AUTOSAR XML (schema 314)
package /ComponentType
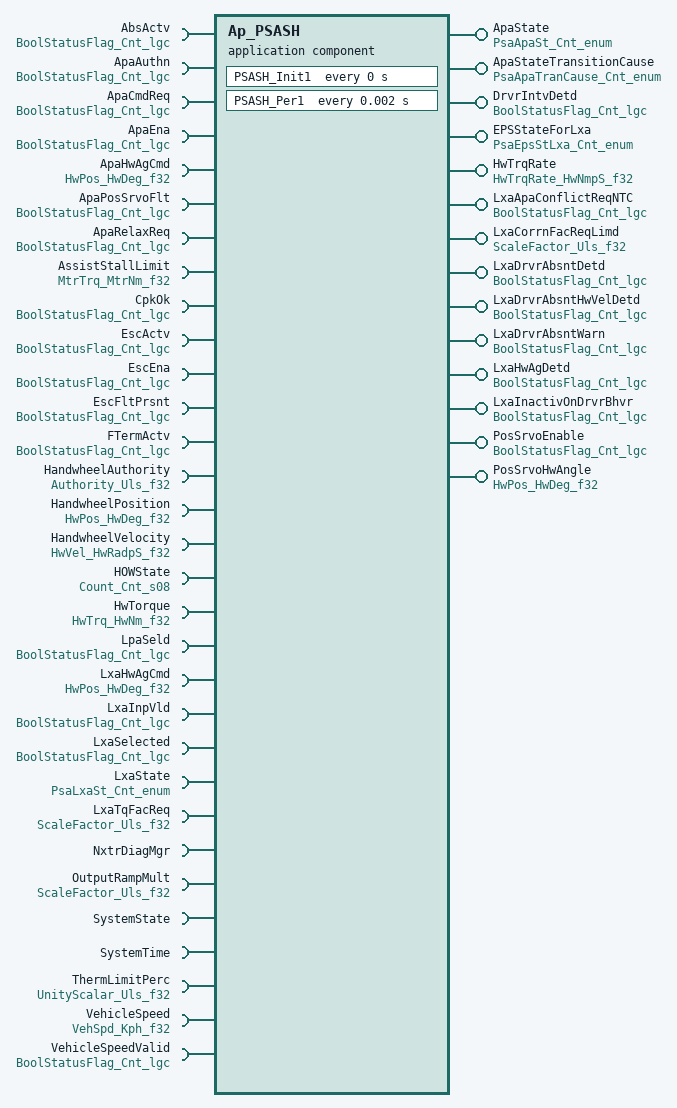
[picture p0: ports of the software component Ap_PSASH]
  application software component type Ap_PSASH
    14 x provide port:
      ApaState: unqueued-sender-com-spec{data-element=Cnt_enum, can-invalidate=false, init-value=D_PSAAPASTINIT_CNT_ENUM}, provided-interface=PsaApaSt_Cnt_enum
      ApaStateTransitionCause: unqueued-sender-com-spec{data-element=Cnt_enum, can-invalidate=false, init-value=D_PSAAPATRANCAUSEINIT_CNT_ENUM}, provided-interface=PsaApaTranCause_Cnt_enum  # Indicates the transition reason of the Automatic Parking Assist State
      DrvrIntvDetd: unqueued-sender-com-spec{data-element=Cnt_lgc, can-invalidate=false, init-value=D_FALSE_CNT_LGC}, provided-interface=BoolStatusFlag_Cnt_lgc  # True -> Hands are on the wheel.
      EPSStateForLxa: unqueued-sender-com-spec{data-element=Cnt_enum, can-invalidate=false, init-value=D_PSAEPSSTLXAINIT_CNT_ENUM}, provided-interface=PsaEpsStLxa_Cnt_enum  # EPS State For LXA
      HwTrqRate: unqueued-sender-com-spec{data-element=HwNmpS_f32, can-invalidate=false, init-value=D_ZERO_ULS_F32}, provided-interface=HwTrqRate_HwNmpS_f32  # Computes Handwheel Torque gradient during LXA command
      LxaApaConflictReqNTC: unqueued-sender-com-spec{data-element=Cnt_lgc, can-invalidate=false, init-value=D_FALSE_CNT_LGC}, provided-interface=BoolStatusFlag_Cnt_lgc  # True means that NTC VLF_20 has been set to FAILED at least one time.
      LxaCorrnFacReqLimd: unqueued-sender-com-spec{data-element=Uls_f32, can-invalidate=false, init-value=D_ZERO_ULS_F32}, provided-interface=ScaleFactor_Uls_f32  # If equal to 1, then the trajectory correction is maximal. If equal to 0, then the trajectory correction is minimal.
      LxaDrvrAbsntDetd: unqueued-sender-com-spec{data-element=Cnt_lgc, can-invalidate=false, init-value=D_FALSE_CNT_LGC}, provided-interface=BoolStatusFlag_Cnt_lgc  # True = Lxa is inactive or driver absent detected
      LxaDrvrAbsntHwVelDetd: unqueued-sender-com-spec{data-element=Cnt_lgc, can-invalidate=false, init-value=D_FALSE_CNT_LGC}, provided-interface=BoolStatusFlag_Cnt_lgc  # True means Lxa has been deactivated on handwheel velocity.
      LxaDrvrAbsntWarn: unqueued-sender-com-spec{data-element=Cnt_lgc, can-invalidate=false, init-value=D_FALSE_CNT_LGC}, provided-interface=BoolStatusFlag_Cnt_lgc  # True means a warning that hands are not on the wheel.
      LxaHwAgDetd: unqueued-sender-com-spec{data-element=Cnt_lgc, can-invalidate=false, init-value=D_FALSE_CNT_LGC}, provided-interface=BoolStatusFlag_Cnt_lgc  # True means LXA has been deactivated on handwheel angle.
      LxaInactivOnDrvrBhvr: unqueued-sender-com-spec{data-element=Cnt_lgc, can-invalidate=false, init-value=D_FALSE_CNT_LGC}, provided-interface=BoolStatusFlag_Cnt_lgc  # LXA Inactive on Driver Behavior
      PosSrvoEnable: unqueued-sender-com-spec{data-element=Cnt_lgc, can-invalidate=false, init-value=D_FALSE_CNT_LGC}, provided-interface=BoolStatusFlag_Cnt_lgc  # True means Position Servo is enabled.
      PosSrvoHwAngle: unqueued-sender-com-spec{data-element=HwDeg_f32, can-invalidate=false, init-value=D_ZERO_ULS_F32}, provided-interface=HwPos_HwDeg_f32  # Tracking angle.
    31 x require port:
      AbsActv: unqueued-receiver-com-spec{data-element=Cnt_lgc, init-value=D_FALSE_CNT_LGC}, required-interface=BoolStatusFlag_Cnt_lgc  # CAN signal indicating whether ABS is active or not.
      ApaAuthn: unqueued-receiver-com-spec{data-element=Cnt_lgc, init-value=D_FALSE_CNT_LGC}, required-interface=BoolStatusFlag_Cnt_lgc  # True: Ignition is running and auto park function is authorized.
      ApaCmdReq: unqueued-receiver-com-spec{data-element=Cnt_lgc, init-value=D_FALSE_CNT_LGC}, required-interface=BoolStatusFlag_Cnt_lgc  # True: Automatic Parking Assist Command is requested.
      ApaEna: unqueued-receiver-com-spec{data-element=Cnt_lgc, init-value=D_FALSE_CNT_LGC}, required-interface=BoolStatusFlag_Cnt_lgc  # True: if the coding variant of Automatic Parking Assist is enabled
      ApaHwAgCmd: unqueued-receiver-com-spec{data-element=HwDeg_f32, init-value=D_ZERO_ULS_F32}, required-interface=HwPos_HwDeg_f32  # Handwheel position set point for Automatic Parking Assist.
      ApaPosSrvoFlt: unqueued-receiver-com-spec{data-element=Cnt_lgc, init-value=D_FALSE_CNT_LGC}, required-interface=BoolStatusFlag_Cnt_lgc  # True: If an NTC is detected due to fact that Automatic Parking ASsist is still active during a vehicle speed greater than a certain threshold
      ApaRelaxReq: unqueued-receiver-com-spec{data-element=Cnt_lgc, init-value=D_FALSE_CNT_LGC}, required-interface=BoolStatusFlag_Cnt_lgc  # True: Temporary request to hold the Automatic Parking Assist command.
      AssistStallLimit: unqueued-receiver-com-spec{data-element=MtrNm_f32, init-value=D_MTRTRQCMDHILMT_MTRNM_F32}, required-interface=MtrTrq_MtrNm_f32  # Motor is stalled when Stall limit is lower or equal than a certain calibrated threshold
      CpkOk: unqueued-receiver-com-spec{data-element=Cnt_lgc, init-value=D_FALSE_CNT_LGC}, required-interface=BoolStatusFlag_Cnt_lgc  # True: All CAN signal used by Automatic Parking Assist are valid.
      EscActv: unqueued-receiver-com-spec{data-element=Cnt_lgc, init-value=D_FALSE_CNT_LGC}, required-interface=BoolStatusFlag_Cnt_lgc  # True: Electrical stability control is active
      EscEna: unqueued-receiver-com-spec{data-element=Cnt_lgc, init-value=D_FALSE_CNT_LGC}, required-interface=BoolStatusFlag_Cnt_lgc  # True: Electronic Stability Control is enabled.
      EscFltPrsnt: unqueued-receiver-com-spec{data-element=Cnt_lgc, init-value=D_TRUE_CNT_LGC}, required-interface=BoolStatusFlag_Cnt_lgc  # True: Fault present on Electronic Stability Control
      FTermActv: unqueued-receiver-com-spec{data-element=Cnt_lgc, init-value=D_FALSE_CNT_LGC}, required-interface=BoolStatusFlag_Cnt_lgc  # True: Fault term is active
      HandwheelAuthority: unqueued-receiver-com-spec{data-element=Uls_f32, init-value=D_ZERO_ULS_F32}, required-interface=Authority_Uls_f32  # Handwheel Authority signal whichis used in order to determine APA State and LXA State.
      HandwheelPosition: unqueued-receiver-com-spec{data-element=HwDeg_f32, init-value=D_ZERO_ULS_F32}, required-interface=HwPos_HwDeg_f32  # Handwheel Position Signal. Used in all kinds of computations: LXA State, APA State and LXA Driver Behavior
      HandwheelVelocity: unqueued-receiver-com-spec{data-element=HwRadpS_f32, init-value=D_ZERO_ULS_F32}, required-interface=HwVel_HwRadpS_f32  # Handwheel Velocity. Used for calculating handwheel velocity thresholds used in LXA Driver Behavior algorithm to determine its outputs.
      HOWState: unqueued-receiver-com-spec{data-element=Cnt_s08, init-value=D_ZERO_CNT_S8}, required-interface=Count_Cnt_s08  # Computes if hands are on the wheel or not with a levelof confident goi'ng from -3 to 3
      HwTorque: unqueued-receiver-com-spec{data-element=HwNm_f32, init-value=D_ZERO_ULS_F32}, required-interface=HwTrq_HwNm_f32  # Standard Handwheel Torque used in LXA Driver Behavior algorithm.
      LpaSeld: unqueued-receiver-com-spec{data-element=Cnt_lgc, init-value=D_FALSE_CNT_LGC}, required-interface=BoolStatusFlag_Cnt_lgc  # To select between LKA (Lane Keeping Assist) & LPA (Lane Positioning Assist). 0 = LPA Not Selected (LKA Active), 1 - Otherwise
      LxaHwAgCmd: unqueued-receiver-com-spec{data-element=HwDeg_f32, init-value=D_ZERO_ULS_F32}, required-interface=HwPos_HwDeg_f32  # Handwheel position set point for LXA
      LxaInpVld: unqueued-receiver-com-spec{data-element=Cnt_lgc, init-value=D_FALSE_CNT_LGC}, required-interface=BoolStatusFlag_Cnt_lgc  # True: CAN signals used by the LXA function are valid
      LxaSelected: unqueued-receiver-com-spec{data-element=Cnt_lgc, init-value=D_FALSE_CNT_LGC}, required-interface=BoolStatusFlag_Cnt_lgc  # Variand coding to enable/disbale the Lxa function
      LxaState: unqueued-receiver-com-spec{data-element=Cnt_enum, init-value=D_PSALXASTINIT_CNT_ENUM}, required-interface=PsaLxaSt_Cnt_enum  # Lane Keeping Assist comand request to change the EPS state for LKA
      LxaTqFacReq: unqueued-receiver-com-spec{data-element=Uls_f32, init-value=D_ZERO_ULS_F32}, required-interface=ScaleFactor_Uls_f32  # A scale factor for LXA Command.
      NxtrDiagMgr: required-com-specs=[GetNTCActive, GetNTCFailed, GetNTCStatus, SetNTCStatus], required-interface=NxtrDiagMgr
      OutputRampMult: unqueued-receiver-com-spec{data-element=Uls_f32, init-value=D_ZERO_ULS_F32}, required-interface=ScaleFactor_Uls_f32  # Signal used in computing internal EPS State which is part of EPS State For Lxa computations.
      SystemState: required-interface=SystemState  # Indicates the system state.
      SystemTime: required-interface=SystemTime
        required-com-specs:
          DtrmnElapsedTime_mS_u16
          DtrmnElapsedTime_mS_u32
          DtrmnElapsedTime_uS_u16
          DtrmnElapsedTime_uS_u32
          GetSystemTime_mS_u32
          GetSystemTime_uS_u32
      ThermLimitPerc: unqueued-receiver-com-spec{data-element=Uls_f32, init-value=D_ZERO_ULS_F32}, required-interface=UnityScalar_Uls_f32  # Thermal Limit is reached when thermal Limit is higher than or equal to a certain calibrated threshold.
      VehicleSpeed: unqueued-receiver-com-spec{data-element=Kph_f32, init-value=D_ZERO_ULS_F32}, required-interface=VehSpd_Kph_f32  # Standard Vehicle Speed signal.
      VehicleSpeedValid: unqueued-receiver-com-spec{data-element=Cnt_lgc, init-value=D_FALSE_CNT_LGC}, required-interface=BoolStatusFlag_Cnt_lgc  # TRUE: Vehicle Speed signal is valid
  internal behavior Ap_PSASH_InternalBehavior: component=Ap_PSASH
    timing event PSASH_Init1_InitEvent: start-on-event=PSASH_Init1, period=0
    timing event TMT_PSASH_Per1: start-on-event=PSASH_Per1, period=0.002
    port-api-options:
      enable-take-address=false, indirect-api=false, port=AbsActv
      enable-take-address=false, indirect-api=false, port=ApaAuthn
      enable-take-address=false, indirect-api=false, port=ApaCmdReq
      enable-take-address=false, indirect-api=false, port=ApaEna
      enable-take-address=false, indirect-api=false, port=ApaHwAgCmd
      enable-take-address=false, indirect-api=false, port=ApaPosSrvoFlt
      enable-take-address=false, indirect-api=false, port=ApaRelaxReq
      enable-take-address=false, indirect-api=false, port=ApaState
      enable-take-address=false, indirect-api=false, port=ApaStateTransitionCause
      enable-take-address=false, indirect-api=false, port=AssistStallLimit
      enable-take-address=false, indirect-api=false, port=CpkOk
      enable-take-address=false, indirect-api=false, port=DrvrIntvDetd
      enable-take-address=false, indirect-api=false, port=EPSStateForLxa
      enable-take-address=false, indirect-api=false, port=EscActv
      enable-take-address=false, indirect-api=false, port=EscEna
      enable-take-address=false, indirect-api=false, port=EscFltPrsnt
      enable-take-address=false, indirect-api=false, port=FTermActv
      enable-take-address=false, indirect-api=false, port=HandwheelAuthority
      enable-take-address=false, indirect-api=false, port=HandwheelPosition
      enable-take-address=false, indirect-api=false, port=HandwheelVelocity
      enable-take-address=false, indirect-api=false, port=HOWState
      enable-take-address=false, indirect-api=false, port=HwTorque
      enable-take-address=false, indirect-api=false, port=HwTrqRate
      enable-take-address=false, indirect-api=false, port=LpaSeld
      enable-take-address=false, indirect-api=false, port=LxaApaConflictReqNTC
      enable-take-address=false, indirect-api=false, port=LxaCorrnFacReqLimd
      enable-take-address=false, indirect-api=false, port=LxaDrvrAbsntDetd
      enable-take-address=false, indirect-api=false, port=LxaDrvrAbsntHwVelDetd
      enable-take-address=false, indirect-api=false, port=LxaDrvrAbsntWarn
      enable-take-address=false, indirect-api=false, port=LxaHwAgCmd
      enable-take-address=false, indirect-api=false, port=LxaHwAgDetd
      enable-take-address=false, indirect-api=false, port=LxaInactivOnDrvrBhvr
      enable-take-address=false, indirect-api=false, port=LxaInpVld
      enable-take-address=false, indirect-api=false, port=LxaSelected
      enable-take-address=false, indirect-api=false, port=LxaState
      enable-take-address=false, indirect-api=false, port=LxaTqFacReq
      enable-take-address=false, indirect-api=false, port=NxtrDiagMgr
      enable-take-address=false, indirect-api=false, port=OutputRampMult
      enable-take-address=false, indirect-api=false, port=PosSrvoEnable
      enable-take-address=false, indirect-api=false, port=PosSrvoHwAngle
      enable-take-address=false, indirect-api=false, port=SystemState
      enable-take-address=false, indirect-api=false, port=SystemTime
      enable-take-address=false, indirect-api=false, port=ThermLimitPerc
      enable-take-address=false, indirect-api=false, port=VehicleSpeed
      enable-take-address=false, indirect-api=false, port=VehicleSpeedValid
    runnable PSASH_Init1  # Function initialization
      sync call SC_NxtrDiagMgr_SetNTCStatus: operation=NxtrDiagMgr.SetNTCStatus, timeout=0
    runnable PSASH_Per1  # Periodic Runnable execute at every 0.002 sec. Shouble be executed before SF020A PosnTrakgServo
      28 x data read access:
        READ_AbsActv_Cnt_lgc: data-element=AbsActv.Cnt_lgc
        READ_ApaAuthn_Cnt_lgc: data-element=ApaAuthn.Cnt_lgc
        READ_ApaCmdReq_Cnt_lgc: data-element=ApaCmdReq.Cnt_lgc
        READ_ApaEna_Cnt_lgc: data-element=ApaEna.Cnt_lgc
        READ_ApaHwAgCmd_HwDeg_f32: data-element=ApaHwAgCmd.HwDeg_f32
        READ_ApaPosSrvoFlt_Cnt_lgc: data-element=ApaPosSrvoFlt.Cnt_lgc
        READ_ApaRelaxReq_Cnt_lgc: data-element=ApaRelaxReq.Cnt_lgc
        READ_AssistStallLimit_MtrNm_f32: data-element=AssistStallLimit.MtrNm_f32
        READ_CpkOk_Cnt_lgc: data-element=CpkOk.Cnt_lgc
        READ_EscActv_Cnt_lgc: data-element=EscActv.Cnt_lgc
        READ_EscEna_Cnt_lgc: data-element=EscEna.Cnt_lgc
        READ_EscFltPrsnt_Cnt_lgc: data-element=EscFltPrsnt.Cnt_lgc
        READ_FTermActv_Cnt_lgc: data-element=FTermActv.Cnt_lgc
        READ_HandwheelAuthority_Uls_f32: data-element=HandwheelAuthority.Uls_f32
        READ_HandwheelPosition_HwDeg_f32: data-element=HandwheelPosition.HwDeg_f32
        READ_HandwheelVelocity_HwRadpS_f32: data-element=HandwheelVelocity.HwRadpS_f32
        READ_HOWState_Cnt_s08: data-element=HOWState.Cnt_s08
        READ_HwTorque_HwNm_f32: data-element=HwTorque.HwNm_f32
        READ_LpaSeld_Cnt_lgc: data-element=LpaSeld.Cnt_lgc
        READ_LxaHwAgCmd_HwDeg_f32: data-element=LxaHwAgCmd.HwDeg_f32
        READ_LxaInpVld_Cnt_lgc: data-element=LxaInpVld.Cnt_lgc
        READ_LxaSelected_Cnt_lgc: data-element=LxaSelected.Cnt_lgc
        READ_LxaState_Cnt_enum: data-element=LxaState.Cnt_enum
        READ_LxaTqFacReq_Uls_f32: data-element=LxaTqFacReq.Uls_f32
        READ_OutputRampMult_Uls_f32: data-element=OutputRampMult.Uls_f32
        READ_ThermLimitPerc_Uls_f32: data-element=ThermLimitPerc.Uls_f32
        READ_VehicleSpeed_Kph_f32: data-element=VehicleSpeed.Kph_f32
        READ_VehicleSpeedValid_Cnt_lgc: data-element=VehicleSpeedValid.Cnt_lgc
      14 x data write access:
        WRITE_ApaState_Cnt_enum: data-element=ApaState.Cnt_enum
        WRITE_ApaStateTransitionCause_Cnt_enum: data-element=ApaStateTransitionCause.Cnt_enum
        WRITE_DrvrIntvDetd_Cnt_lgc: data-element=DrvrIntvDetd.Cnt_lgc
        WRITE_EPSStateForLxa_Cnt_enum: data-element=EPSStateForLxa.Cnt_enum
        WRITE_HwTrqRate_HwNmpS_f32: data-element=HwTrqRate.HwNmpS_f32
        WRITE_LxaApaConflictReqNTC_Cnt_lgc: data-element=LxaApaConflictReqNTC.Cnt_lgc
        WRITE_LxaCorrnFacReqLimd_Uls_f32: data-element=LxaCorrnFacReqLimd.Uls_f32
        WRITE_LxaDrvrAbsntDetd_Cnt_lgc: data-element=LxaDrvrAbsntDetd.Cnt_lgc
        WRITE_LxaDrvrAbsntHwVelDetd_Cnt_lgc: data-element=LxaDrvrAbsntHwVelDetd.Cnt_lgc
        WRITE_LxaDrvrAbsntWarn_Cnt_lgc: data-element=LxaDrvrAbsntWarn.Cnt_lgc
        WRITE_LxaHwAgDetd_Cnt_lgc: data-element=LxaHwAgDetd.Cnt_lgc
        WRITE_LxaInactivOnDrvrBhvr_Cnt_lgc: data-element=LxaInactivOnDrvrBhvr.Cnt_lgc
        WRITE_PosSrvoEnable_Cnt_lgc: data-element=PosSrvoEnable.Cnt_lgc
        WRITE_PosSrvoHwAngle_HwDeg_f32: data-element=PosSrvoHwAngle.HwDeg_f32
      4 x sync call, all with timeout=0:
        SC_NxtrDiagMgr_GetNTCActive: operation=NxtrDiagMgr.GetNTCActive
        SC_NxtrDiagMgr_SetNTCStatus: operation=NxtrDiagMgr.SetNTCStatus
        SC_SystemTime_DtrmnElapsedTime_mS_u32: operation=SystemTime.DtrmnElapsedTime_mS_u32
        SC_SystemTime_GetSystemTime_mS_u32: operation=SystemTime.GetSystemTime_mS_u32
  swc implementation Ap_PSASH_Implementation: behavior=Ap_PSASH_InternalBehavior
    code-descriptors:
      code Code: type=SRC
